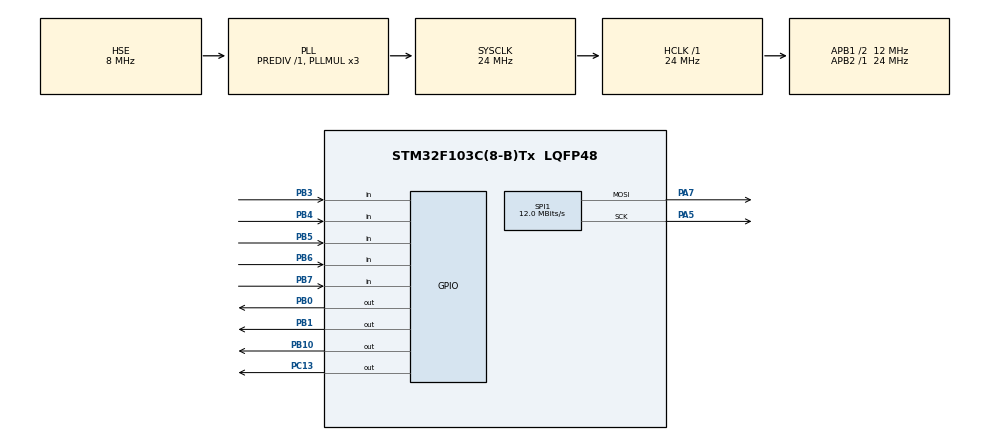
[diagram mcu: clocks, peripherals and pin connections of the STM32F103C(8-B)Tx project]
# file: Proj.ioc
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Dma.Request0=SPI1_TX
Dma.SPI1_TX.0.Direction=DMA_MEMORY_TO_PERIPH
Dma.SPI1_TX.0.Instance=DMA1_Channel3
Dma.SPI1_TX.0.MemDataAlignment=DMA_MDATAALIGN_HALFWORD
Dma.SPI1_TX.0.MemInc=DMA_MINC_ENABLE
Dma.SPI1_TX.0.Mode=DMA_NORMAL
Dma.SPI1_TX.0.PeriphDataAlignment=DMA_PDATAALIGN_HALFWORD
Dma.SPI1_TX.0.PeriphInc=DMA_PINC_DISABLE
Dma.SPI1_TX.0.Priority=DMA_PRIORITY_LOW
Mcu.Family=STM32F1
Mcu.Name=STM32F103C(8-B)Tx
Mcu.Package=LQFP48
NVIC.DMA1_Channel3_IRQn=true\:0\:0\:false\:false\:true\:false\:true\:true
NVIC.PriorityGroup=NVIC_PRIORITYGROUP_4
NVIC.SPI1_IRQn=true\:0\:0\:false\:false\:true\:true\:true\:true
PA13.Mode=Serial_Wire
PA13.Signal=SYS_JTMS-SWDIO
PA14.Mode=Serial_Wire
PA14.Signal=SYS_JTCK-SWCLK
PA5.Mode=TX_Only_Simplex_Unidirect_Master
PA5.Signal=SPI1_SCK
PA7.Mode=TX_Only_Simplex_Unidirect_Master
PA7.Signal=SPI1_MOSI
PB0.Signal=GPIO_Output
PB1.Signal=GPIO_Output
PB10.Signal=GPIO_Output
PB3.GPIO_PuPd=GPIO_PULLUP
PB3.Signal=GPIO_Input
PB4.GPIO_PuPd=GPIO_PULLUP
PB4.Signal=GPIO_Input
PB5.GPIO_PuPd=GPIO_PULLUP
PB5.Signal=GPIO_Input
PB6.GPIO_PuPd=GPIO_PULLUP
PB6.Signal=GPIO_Input
PB7.GPIO_PuPd=GPIO_PULLUP
PB7.Signal=GPIO_Input
PC13-TAMPER-RTC.Signal=GPIO_Output
PD0-OSC_IN.Mode=HSE-External-Oscillator
PD0-OSC_IN.Signal=RCC_OSC_IN
PD1-OSC_OUT.Mode=HSE-External-Oscillator
PD1-OSC_OUT.Signal=RCC_OSC_OUT
ProjectManager.HeapSize=0x200
ProjectManager.StackSize=0x400
ProjectManager.TargetToolchain=STM32CubeIDE
RCC.AHBFreq_Value=24000000
RCC.APB1CLKDivider=RCC_HCLK_DIV2
RCC.APB1Freq_Value=12000000
RCC.APB1TimFreq_Value=24000000
RCC.APB2Freq_Value=24000000
RCC.APB2TimFreq_Value=24000000
RCC.HCLKFreq_Value=24000000
RCC.PLLMUL=RCC_PLL_MUL3
RCC.PLLSourceVirtual=RCC_PLLSOURCE_HSE
RCC.SYSCLKFreq_VALUE=24000000
RCC.SYSCLKSource=RCC_SYSCLKSOURCE_PLLCLK
RCC.USBFreq_Value=24000000
SPI1.BaudRatePrescaler=SPI_BAUDRATEPRESCALER_2
SPI1.CalculateBaudRate=12.0 MBits/s
SPI1.Direction=SPI_DIRECTION_2LINES
SPI1.Mode=SPI_MODE_MASTER
SPI1.VirtualType=VM_MASTER
board=custom

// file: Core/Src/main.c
/* USER CODE BEGIN Header */
/**
  ******************************************************************************
  * @file           : main.c
  * @brief          : Main program body
  ******************************************************************************
  * @attention
  *
  * Copyright (c) 2025 STMicroelectronics.
  * All rights reserved.
  *
  * This software is licensed under terms that can be found in the LICENSE file
  * in the root directory of this software component.
  * If no LICENSE file comes with this software, it is provided AS-IS.
  *
  ******************************************************************************
  */
/* USER CODE END Header */
#include "main.h"
#include "CommonFunc.h"

SPI_HandleTypeDef hspi1;
DMA_HandleTypeDef hdma_spi1_tx;

void SystemClock_Config(void);
static void MX_GPIO_Init(void);
static void MX_DMA_Init(void);
static void MX_SPI1_Init(void);

Game game;
uint32_t X[32];
uint32_t O[32];
int main(void)
{

  /* MCU Configuration--------------------------------------------------------*/

  /* Reset of all peripherals, Initializes the Flash interface and the Systick. */
  HAL_Init();

  /* Configure the system clock */
  SystemClock_Config();

  /* Initialize all configured peripherals */
  MX_GPIO_Init();
  MX_DMA_Init();
  MX_SPI1_Init();
  /* USER CODE BEGIN 2 */
  St7735s_Init();
  NewGame(&game);
  GameMenu();
  /* USER CODE END 2 */

  /* Infinite loop */
  while (1)
  {
	  int button = Button();
	  switch (button){
	  case CLICK:
		  if(game.state == MENU){
			  if(game.cur.second == 0) game.mode = TWO_PLAYER;
			  if(game.cur.second == 1) game.mode = ONE_PLAYER;
			  DrawBoard();
			  St7735s_FillRectangle(6, 22, 36, 36, ST7735_WHITE);
			  game.state = RUNNING;
			  game.player = _X;
			  game.cur.first = 0;
			  game.cur.second = 0;
		  }else if(game.state == RUNNING){
			  if(game.board[game.cur.first][game.cur.second] == EMPTY){
				  game.board[game.cur.first][game.cur.second] = game.player;
				  if(game.mode == TWO_PLAYER){
					  if(game.player == _X)
						  DrawXO(X, 8 + ((BOARD_WIDTH/N) * game.cur.first),
								  24 +((BOARD_HEIGHT/N) * game.cur.second), ST7735_RED, ST7735_WHITE);
					  else DrawXO(O, 8 + ((BOARD_WIDTH/N) * game.cur.first),
							  24 +((BOARD_HEIGHT/N) * game.cur.second), ST7735_BLUE, ST7735_WHITE);
					  if (game.player == _X)game.player = _O;
					  else game.player = _X;
					  game.state = CheckWin(game.board, &game.cur);
					  End(game.state);
				  }else if(game.mode == ONE_PLAYER){
					  DrawXO(X, 8 + ((BOARD_WIDTH/N) * game.cur.first),
					  24 +((BOARD_HEIGHT/N) * game.cur.second), ST7735_RED, ST7735_WHITE);
					  game.state = CheckWin(game.board, &game.cur);
					  End(game.state);
					  if (game.player == _X)game.player = _O;
					  else game.player = _X;
					  if(game.state == RUNNING){
						  BotMove(&game);
						  game.state = CheckWin(game.board, &game.bot_cur);
						  game.board[game.bot_cur.first][game.bot_cur.second] =_O;
						  if (game.player == _X)game.player = _O;
						  else game.player = _X;
						  End(game.state);
					  }
				  }
		      }
		  }
	  break;
	  case UP:
		  if(game.cur.second != 0){
		  if(game.state == MENU) {
			  St7735s_WriteString(36, 40, "Hai nguoi", Font7x10, ST7735_RED, ST7735_WHITE);
			  St7735s_WriteString(36, 90, "Mot nguoi", Font7x10, ST7735_RED, ST7735_BLACK);
			  game.cur.second = 0;
		  }
		  if(game.state == RUNNING) MoveCur(&game, button);
		  }
	  break;
	  case DOWN:
		  if(game.cur.second != 2){
		  if(game.state == MENU){
			  St7735s_WriteString(36, 40, "Hai nguoi", Font7x10, ST7735_RED, ST7735_BLACK);
			  St7735s_WriteString(36, 90, "Mot nguoi", Font7x10, ST7735_RED, ST7735_WHITE);
			  game.cur.second = 1;
		  }if(game.state == RUNNING) MoveCur(&game, button);
		  }
	  break;
	  case RIGHT:
		  if((game.cur.first < 2)&&(game.state == RUNNING))
		  MoveCur(&game, button);
	  break;
	  case LEFT:
		  if((game.cur.first > 0)&&(game.state == RUNNING))
		  MoveCur(&game, button);
	  break;
	  default :{}
	  }
  }
}

void SystemClock_Config(void)
{
  RCC_OscInitTypeDef RCC_OscInitStruct = {0};
  RCC_ClkInitTypeDef RCC_ClkInitStruct = {0};

  /** Initializes the RCC Oscillators according to the specified parameters
  * in the RCC_OscInitTypeDef structure.
  */
  RCC_OscInitStruct.OscillatorType = RCC_OSCILLATORTYPE_HSE;
  RCC_OscInitStruct.HSEState = RCC_HSE_ON;
  RCC_OscInitStruct.HSEPredivValue = RCC_HSE_PREDIV_DIV1;
  RCC_OscInitStruct.HSIState = RCC_HSI_ON;
  RCC_OscInitStruct.PLL.PLLState = RCC_PLL_ON;
  RCC_OscInitStruct.PLL.PLLSource = RCC_PLLSOURCE_HSE;
  RCC_OscInitStruct.PLL.PLLMUL = RCC_PLL_MUL3;
  if (HAL_RCC_OscConfig(&RCC_OscInitStruct) != HAL_OK)
  {
    Error_Handler();
  }

  /** Initializes the CPU, AHB and APB buses clocks
  */
  RCC_ClkInitStruct.ClockType = RCC_CLOCKTYPE_HCLK|RCC_CLOCKTYPE_SYSCLK
                              |RCC_CLOCKTYPE_PCLK1|RCC_CLOCKTYPE_PCLK2;
  RCC_ClkInitStruct.SYSCLKSource = RCC_SYSCLKSOURCE_PLLCLK;
  RCC_ClkInitStruct.AHBCLKDivider = RCC_SYSCLK_DIV1;
  RCC_ClkInitStruct.APB1CLKDivider = RCC_HCLK_DIV2;
  RCC_ClkInitStruct.APB2CLKDivider = RCC_HCLK_DIV1;

  if (HAL_RCC_ClockConfig(&RCC_ClkInitStruct, FLASH_LATENCY_0) != HAL_OK)
  {
    Error_Handler();
  }
}

static void MX_SPI1_Init(void)
{

  /* SPI1 parameter configuration*/
  hspi1.Instance = SPI1;
  hspi1.Init.Mode = SPI_MODE_MASTER;
  hspi1.Init.Direction = SPI_DIRECTION_2LINES;
  hspi1.Init.DataSize = SPI_DATASIZE_8BIT;
  hspi1.Init.CLKPolarity = SPI_POLARITY_LOW;
  hspi1.Init.CLKPhase = SPI_PHASE_1EDGE;
  hspi1.Init.NSS = SPI_NSS_SOFT;
  hspi1.Init.BaudRatePrescaler = SPI_BAUDRATEPRESCALER_2;
  hspi1.Init.FirstBit = SPI_FIRSTBIT_MSB;
  hspi1.Init.TIMode = SPI_TIMODE_DISABLE;
  hspi1.Init.CRCCalculation = SPI_CRCCALCULATION_DISABLE;
  hspi1.Init.CRCPolynomial = 10;
  if (HAL_SPI_Init(&hspi1) != HAL_OK)
  {
    Error_Handler();
  }

}

static void MX_DMA_Init(void)
{

  /* DMA controller clock enable */
  __HAL_RCC_DMA1_CLK_ENABLE();

  /* DMA interrupt init */
  /* DMA1_Channel3_IRQn interrupt configuration */
  HAL_NVIC_SetPriority(DMA1_Channel3_IRQn, 0, 0);
  HAL_NVIC_EnableIRQ(DMA1_Channel3_IRQn);

}

static void MX_GPIO_Init(void)
{
  GPIO_InitTypeDef GPIO_InitStruct = {0};

  /* GPIO Ports Clock Enable */
  __HAL_RCC_GPIOC_CLK_ENABLE();
  __HAL_RCC_GPIOD_CLK_ENABLE();
  __HAL_RCC_GPIOA_CLK_ENABLE();
  __HAL_RCC_GPIOB_CLK_ENABLE();

  /*Configure GPIO pin Output Level */
  HAL_GPIO_WritePin(GPIOC, GPIO_PIN_13, GPIO_PIN_RESET);

  /*Configure GPIO pin Output Level */
  HAL_GPIO_WritePin(GPIOB, GPIO_PIN_0|GPIO_PIN_1|GPIO_PIN_10, GPIO_PIN_RESET);

  /*Configure GPIO pin : PC13 */
  GPIO_InitStruct.Pin = GPIO_PIN_13;
  GPIO_InitStruct.Mode = GPIO_MODE_OUTPUT_PP;
  GPIO_InitStruct.Pull = GPIO_NOPULL;
  GPIO_InitStruct.Speed = GPIO_SPEED_FREQ_LOW;
  HAL_GPIO_Init(GPIOC, &GPIO_InitStruct);

  /*Configure GPIO pins : PB0 PB1 PB10 */
  GPIO_InitStruct.Pin = GPIO_PIN_0|GPIO_PIN_1|GPIO_PIN_10;
  GPIO_InitStruct.Mode = GPIO_MODE_OUTPUT_PP;
  GPIO_InitStruct.Pull = GPIO_NOPULL;
  GPIO_InitStruct.Speed = GPIO_SPEED_FREQ_LOW;
  HAL_GPIO_Init(GPIOB, &GPIO_InitStruct);

  /*Configure GPIO pins : PB3 PB4 PB5 PB6
                           PB7 */
  GPIO_InitStruct.Pin = GPIO_PIN_3|GPIO_PIN_4|GPIO_PIN_5|GPIO_PIN_6
                          |GPIO_PIN_7;
  GPIO_InitStruct.Mode = GPIO_MODE_INPUT;
  GPIO_InitStruct.Pull = GPIO_PULLUP;
  HAL_GPIO_Init(GPIOB, &GPIO_InitStruct);

}

void Error_Handler(void)
{
  __disable_irq();
  while (1)
  {
  }
}
